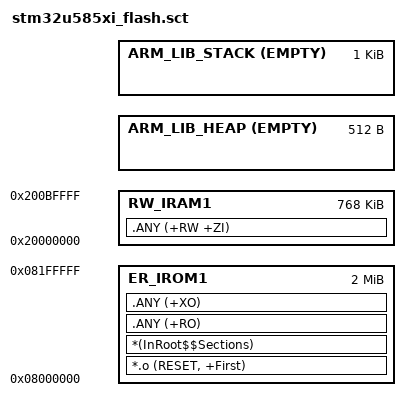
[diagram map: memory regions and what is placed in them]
#! armclang -E --target=arm-arm-none-eabi -mcpu=cortex-m33 -xc
; command above MUST be in first line (no comment above!)



; ******************************************************************************
; **
; **  File        : stm32u585xi_flash.sct
; **
; **  Abstract    : Linker script for stm32u585xi Device from STM32U585 series
; **                      2Mbytes FLASH
; **                      768Kbytes RAM
; **
; **                Set heap size, stack size and stack location according
; **                to application requirements.
; **
; **                Set memory bank area and size if external memory is used.
; **
; **  Target      : STMicroelectronics STM32
; **
; **  Distribution: The file is distributed as is without any warranty
; **                of any kind.
; **
; *****************************************************************************
; ** @attention
; **
; ** Copyright (c) 2023-2024 STMicroelectronics.
; ** All rights reserved.
; **
; ** This software is licensed under terms that can be found in the LICENSE file
; ** in the root directory of this software component.
; ** If no LICENSE file comes with this software, it is provided AS-IS.
; **
; *****************************************************************************



#define __STACK_SIZE    0x00000400
#define __HEAP_SIZE     0x00000200

; *************************************************************
; *** Scatter-Loading Description File generated by uVision ***
; *************************************************************

LR_IROM1 0x08000000 0x00200000  {    ; load region size_region
  ER_IROM1 0x08000000 0x00200000  {  ; load address = execution address
   *.o (RESET, +First)
   *(InRoot$$Sections)
   .ANY (+RO)
   .ANY (+XO)
  }

  RW_IRAM1 0x20000000 0x000C0000  {  ; RW data
   .ANY (+RW +ZI)
  }

  ARM_LIB_HEAP  AlignExpr(+0, 8) EMPTY  __HEAP_SIZE  {   ; Reserve empty region for heap
  }

  ARM_LIB_STACK AlignExpr(+0, 8) EMPTY  __STACK_SIZE {   ; Reserve empty region for stack
  }
}
